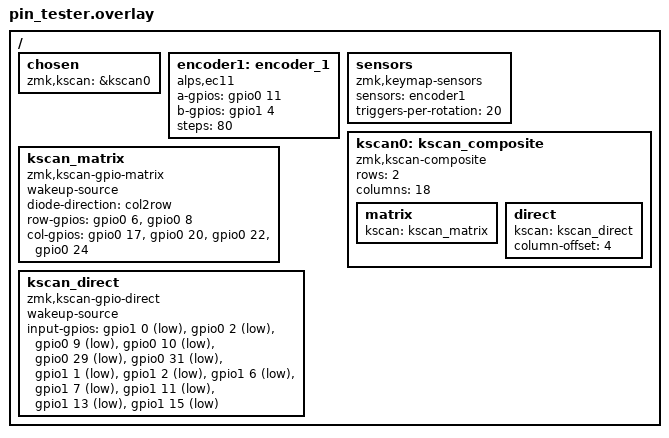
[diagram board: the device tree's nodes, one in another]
/ {
    chosen {
        zmk,kscan = &kscan0;
    };

    // Definir el encoder EC11
    encoder1: encoder_1 {
        compatible = "alps,ec11";
        a-gpios = <&gpio0 11 (GPIO_ACTIVE_HIGH | GPIO_PULL_UP)>;  // P0.11 (CLK)
        b-gpios = <&gpio1 4 (GPIO_ACTIVE_HIGH | GPIO_PULL_UP)>;   // P1.04 (DT)
        steps = <80>;
        status = "okay";
    };

    // Registro de sensors para el encoder
    sensors: sensors {
        compatible = "zmk,keymap-sensors";
        sensors = <&encoder1>;
        triggers-per-rotation = <20>;
    };

    kscan0: kscan_composite {
        compatible = "zmk,kscan-composite";
        rows = <2>;
        columns = <18>;

        matrix {
            kscan = <&kscan_matrix>;
        };

        direct {
            kscan = <&kscan_direct>;
            column-offset = <4>;
        };
    };

    kscan_matrix: kscan_matrix {
        compatible = "zmk,kscan-gpio-matrix";
        wakeup-source;
        
        diode-direction = "col2row";
        
        row-gpios
            = <&gpio0 6 (GPIO_ACTIVE_HIGH | GPIO_PULL_DOWN)>   // Fila 1
            , <&gpio0 8 (GPIO_ACTIVE_HIGH | GPIO_PULL_DOWN)>   // Fila 2
            ;
        
        col-gpios
            = <&gpio0 17 GPIO_ACTIVE_HIGH>  // Columna 1
            , <&gpio0 20 GPIO_ACTIVE_HIGH>  // Columna 2
            , <&gpio0 22 GPIO_ACTIVE_HIGH>  // Columna 3
            , <&gpio0 24 GPIO_ACTIVE_HIGH>  // Columna 4
            ;
    };

    kscan_direct: kscan_direct {
        compatible = "zmk,kscan-gpio-direct";
        wakeup-source;

        input-gpios
            = <&gpio1 0 (GPIO_ACTIVE_LOW | GPIO_PULL_UP)>   // P1.00 - Switch del encoder
            , <&gpio0 2 (GPIO_ACTIVE_LOW | GPIO_PULL_UP)>   // P0.02
            , <&gpio0 9 (GPIO_ACTIVE_LOW | GPIO_PULL_UP)>   // P0.09
            , <&gpio0 10 (GPIO_ACTIVE_LOW | GPIO_PULL_UP)>  // P0.10
            , <&gpio0 29 (GPIO_ACTIVE_LOW | GPIO_PULL_UP)>  // P0.29
            , <&gpio0 31 (GPIO_ACTIVE_LOW | GPIO_PULL_UP)>  // P0.31
            , <&gpio1 1 (GPIO_ACTIVE_LOW | GPIO_PULL_UP)>   // P1.01
            , <&gpio1 2 (GPIO_ACTIVE_LOW | GPIO_PULL_UP)>   // P1.02
            , <&gpio1 6 (GPIO_ACTIVE_LOW | GPIO_PULL_UP)>   // P1.06
            , <&gpio1 7 (GPIO_ACTIVE_LOW | GPIO_PULL_UP)>   // P1.07
            , <&gpio1 11 (GPIO_ACTIVE_LOW | GPIO_PULL_UP)>  // P1.11
            , <&gpio1 13 (GPIO_ACTIVE_LOW | GPIO_PULL_UP)>  // P1.13
            , <&gpio1 15 (GPIO_ACTIVE_LOW | GPIO_PULL_UP)>  // P1.15
            ;
    };
};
